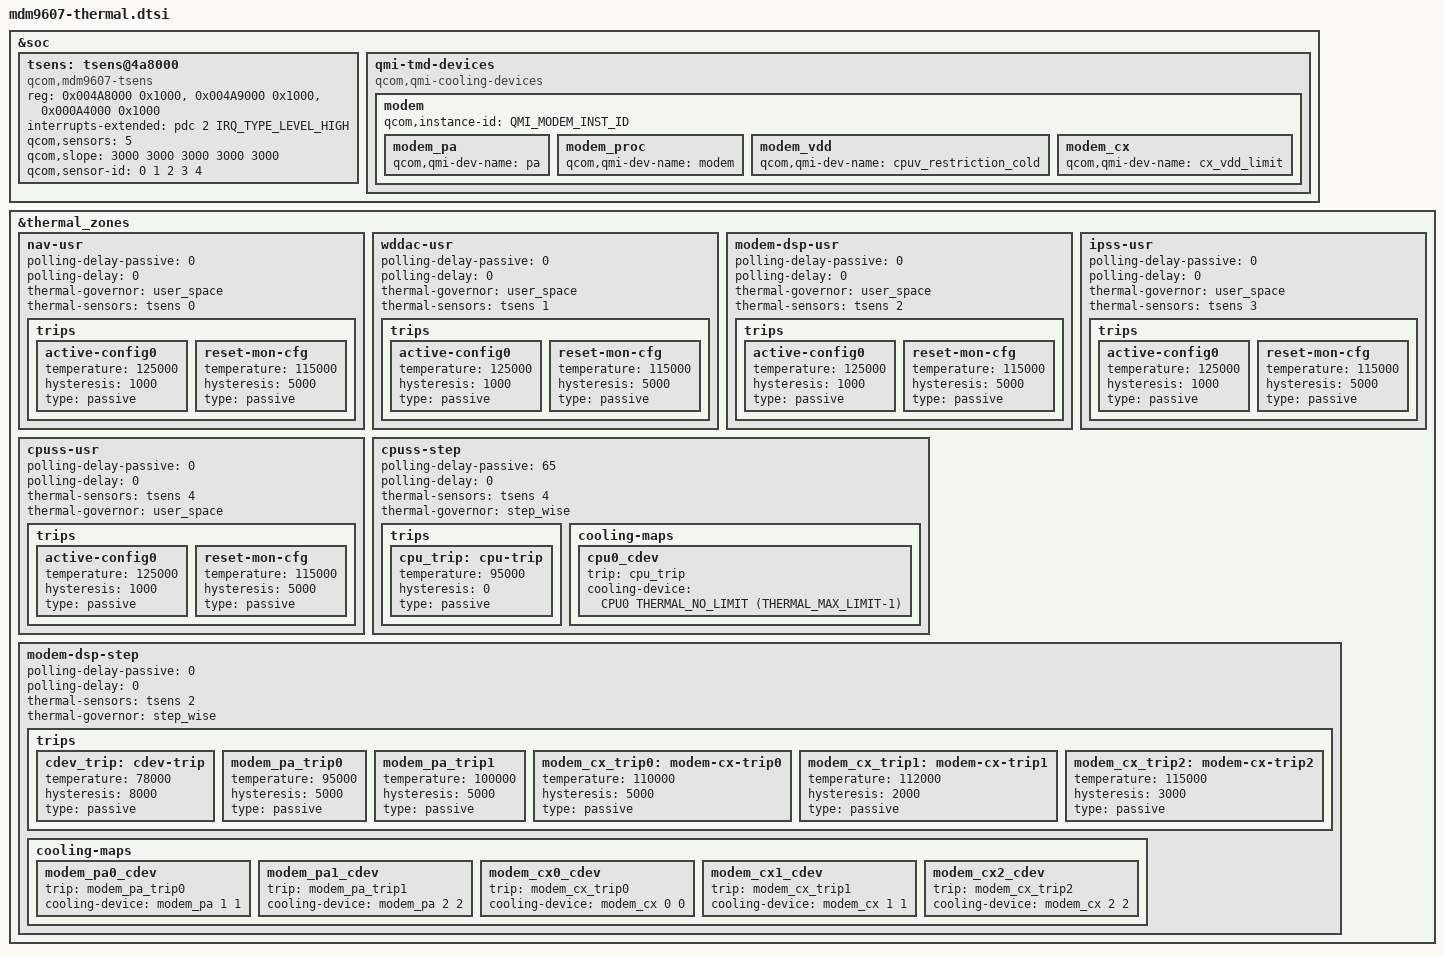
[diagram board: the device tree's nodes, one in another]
#include <dt-bindings/thermal/thermal.h>
#include <dt-bindings/thermal/thermal_qti.h>

&soc {
	 tsens: tsens@4a8000 {
		compatible = "qcom,mdm9607-tsens";
		reg = <0x004A8000 0x1000>,
			<0x004A9000 0x1000>,
			<0x000A4000  0x1000>;
		reg-names ="tsens_srot_physical",
			"tsens_tm_physical",
			"tsens_eeprom_physical";
		interrupts-extended = <&pdc 2 IRQ_TYPE_LEVEL_HIGH>;
		interrupt-names = "tsens-upper-lower";
		qcom,sensors = <5>;
		qcom,slope = <3000 3000 3000 3000 3000>;
		qcom,sensor-id = <0 1 2 3 4>;
		#thermal-sensor-cells = <1>;
	};

	qmi-tmd-devices {
		compatible = "qcom,qmi-cooling-devices";

		modem {
			qcom,instance-id = <QMI_MODEM_INST_ID>;

		modem_pa: modem_pa {
				qcom,qmi-dev-name = "pa";
				#cooling-cells = <2>;
			};

		modem_proc: modem_proc {
				qcom,qmi-dev-name = "modem";
				#cooling-cells = <2>;
			};

		modem_vdd: modem_vdd {
				qcom,qmi-dev-name = "cpuv_restriction_cold";
				#cooling-cells = <2>;
			};

		modem_cx: modem_cx {
				qcom,qmi-dev-name = "cx_vdd_limit";
				#cooling-cells = <2>;
			};
		};
	};
};

&thermal_zones {
	nav-usr {
		polling-delay-passive = <0>;
		polling-delay = <0>;
		thermal-governor = "user_space";
		thermal-sensors = <&tsens 0>;
		trips {
			active-config0 {
				temperature = <125000>;
				hysteresis = <1000>;
				type = "passive";
			};

			reset-mon-cfg {
				temperature = <115000>;
				hysteresis = <5000>;
				type = "passive";
			};
		};
	};

	wddac-usr {
		polling-delay-passive = <0>;
		polling-delay = <0>;
		thermal-governor = "user_space";
		thermal-sensors = <&tsens 1>;
		trips {
			active-config0 {
				temperature = <125000>;
				hysteresis = <1000>;
				type = "passive";
			};

			reset-mon-cfg {
				temperature = <115000>;
				hysteresis = <5000>;
				type = "passive";
			};
		};
	};

	modem-dsp-usr {
		polling-delay-passive = <0>;
		polling-delay = <0>;
		thermal-governor = "user_space";
		thermal-sensors = <&tsens 2>;
		trips {
			active-config0 {
				temperature = <125000>;
				hysteresis = <1000>;
				type = "passive";
			};

			reset-mon-cfg {
				temperature = <115000>;
				hysteresis = <5000>;
				type = "passive";
			};
		};
	};

	ipss-usr {
		polling-delay-passive = <0>;
		polling-delay = <0>;
		thermal-governor = "user_space";
		thermal-sensors = <&tsens 3>;
		trips {
		active-config0 {
				temperature = <125000>;
				hysteresis = <1000>;
				type = "passive";
			};

			reset-mon-cfg {
				temperature = <115000>;
				hysteresis = <5000>;
				type = "passive";
			};
		};
	};

	cpuss-usr {
		polling-delay-passive = <0>;
		polling-delay = <0>;
		thermal-sensors = <&tsens 4>;
		thermal-governor = "user_space";
		trips {
			active-config0 {
				temperature = <125000>;
				hysteresis = <1000>;
				type = "passive";
			};

			reset-mon-cfg {
				temperature = <115000>;
				hysteresis = <5000>;
				type = "passive";
			};
		};
	};

	cpuss-step {
		polling-delay-passive = <65>;
		polling-delay = <0>;
		thermal-sensors = <&tsens 4>;
		thermal-governor = "step_wise";
		trips {
			cpu_trip:cpu-trip  {
				temperature = <95000>;
				hysteresis = <0>;
				type = "passive";
			};
		};

		cooling-maps {
			cpu0_cdev {
				trip = <&cpu_trip>;
				cooling-device =
					<&CPU0 THERMAL_NO_LIMIT
						(THERMAL_MAX_LIMIT-1)>;
			};
		};
	};

	modem-dsp-step {
		polling-delay-passive = <0>;
		polling-delay = <0>;
		thermal-sensors = <&tsens 2>;
		thermal-governor = "step_wise";
		trips {
			cdev_trip: cdev-trip {
				temperature = <78000>;
				hysteresis = <8000>;
				type = "passive";
			};

			modem_pa_trip0: modem_pa_trip0 {
				temperature = <95000>;
				hysteresis = <5000>;
				type = "passive";
			};

			modem_pa_trip1: modem_pa_trip1 {
				temperature = <100000>;
				hysteresis = <5000>;
				type = "passive";
			};

			modem_cx_trip0: modem-cx-trip0  {
				temperature = <110000>;
				hysteresis = <5000>;
				type = "passive";
			};

			modem_cx_trip1: modem-cx-trip1 {
				temperature = <112000>;
				hysteresis = <2000>;
				type = "passive";
			};

			modem_cx_trip2: modem-cx-trip2 {
				temperature = <115000>;
				hysteresis = <3000>;
				type = "passive";
			};
		};

		cooling-maps {
			modem_pa0_cdev {
				trip = <&modem_pa_trip0>;
				cooling-device = <&modem_pa 1 1>;
			};

			modem_pa1_cdev {
				trip = <&modem_pa_trip1>;
				cooling-device = <&modem_pa 2 2>;
			};

			modem_cx0_cdev {
				trip = <&modem_cx_trip0>;
				cooling-device = <&modem_cx 0 0>;
			};

			modem_cx1_cdev {
				trip = <&modem_cx_trip1>;
				cooling-device = <&modem_cx 1 1>;
			};

			modem_cx2_cdev {
				trip = <&modem_cx_trip2>;
				cooling-device = <&modem_cx 2 2>;
			};
		};
	};
};
